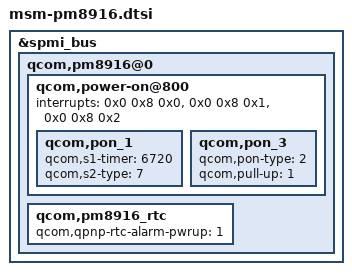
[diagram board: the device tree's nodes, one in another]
/* Copyright (c) 2013-2015, The Linux Foundation. All rights reserved.
 *
 * This program is free software; you can redistribute it and/or modify
 * it under the terms of the GNU General Public License version 2 and
 * only version 2 as published by the Free Software Foundation.
 *
 * This program is distributed in the hope that it will be useful,
 * but WITHOUT ANY WARRANTY; without even the implied warranty of
 * MERCHANTABILITY or FITNESS FOR A PARTICULAR PURPOSE.  See the
 * GNU General Public License for more details.
 */

&spmi_bus {
	qcom,pm8916@0 {
		qcom,power-on@800 {
			interrupts = <0x0 0x8 0x0>,
				     <0x0 0x8 0x1>,
				     <0x0 0x8 0x2>;
			interrupt-names = "kpdpwr", "resin", "cblpwr";

			qcom,pon_1 {
				qcom,s1-timer = <6720>;
				qcom,s2-type = <7>;
			};

			qcom,pon_3 {
				qcom,pon-type = <2>;
				qcom,pull-up = <1>;
			};
		};

		qcom,pm8916_rtc {
			qcom,qpnp-rtc-alarm-pwrup = <1>;
		};
	};
};
